# RasbperryPi register map
File version: 1
Registers are 32-bit, read-write, reset 0x0 unless marked. A register's access mark holds for its fields unless they carry their own. Offsets are from the block's base; [hi:lo] are bit positions; {n}, {i} and the like mark numbered series; 'fields as' and 'values as' point back to an identical list.

## USB — Derived from usb.h apb_id: 0x75736230
Base 0x7E980000
0x00 GOTGCTL 20-bit reset not defined
  [19] B_SES_VLD, [18] A_SES_VLD, [17] DBNC_TIME, [16] CON_ID_STS, [15:12] _, [11] DEV_HNP_EN, [10] HST_SET_HNP_EN, [9] HNP_REQ, [8] HST_NEG_SCS, [7:2] _, [1] SES_REQ, [0] SES_REQ_SCS
0x00 HPTXFSIZ reset not defined
  [31:0] data
0x00 HCFG 3-bit reset not defined
  [2] LS_SUPP, [1:0] LS_PHY_CLK_SEL
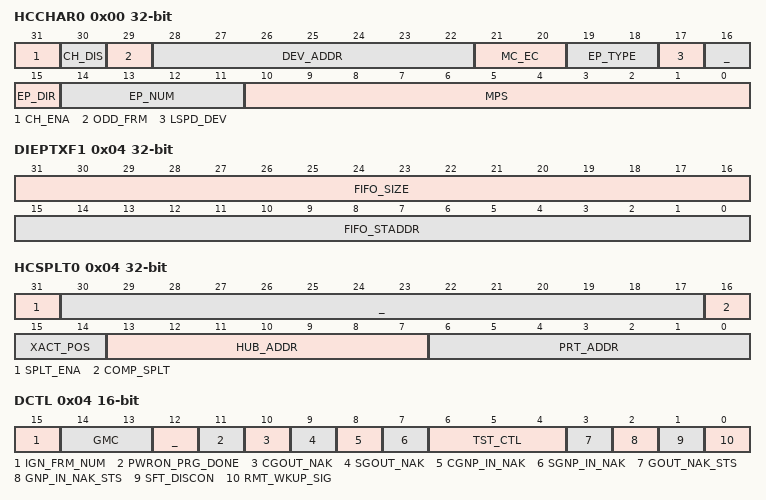
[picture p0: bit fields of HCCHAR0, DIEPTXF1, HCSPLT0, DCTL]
0x00 HCCHAR0 reset not defined
  [31] CH_ENA, [30] CH_DIS, [29] ODD_FRM, [28:22] DEV_ADDR, [21:20] MC_EC, [19:18] EP_TYPE, [17] LSPD_DEV, [16] _, [15] EP_DIR, [14:11] EP_NUM, [10:0] MPS
0x00 DCFG 26-bit reset not defined
  [25:24] PER_SCH_INTV, [23] DESC_DMA, [22:18] EP_MIS_CNT, [17:13] _, [12:11] PER_FR_INT, [10:4] DEV_ADDR, [3] _, [2] NZ_STS_OUT_HSHK, [1:0] DEV_SPD
0x00 DIEPCTL0 reset not defined
  [31] ENA, [30] DIS, [29] SET_D1_PID, [29] SET_ODD_FR, [28] SET_D0_PID, [28] SET_EVEN_FR, [27] SNAK, [26] CNAK, [25:22] TXF_NUM, [21] STALL, [20] SNP, [19:18] TYPE, [17] NAK_STS, [16] DPID, [16] EO_FR_NUM, [15] USB_ACT_EP, [14:11] NEXT_EP, [10:0] MPS
0x00 DIEPCTL8 reset not defined
  [31:0] data
0x00 DOEPCTL0 reset not defined
  fields as DIEPCTL0
0x00 DOEPCTL8 reset not defined
  [31:0] data
0x00 PCGCR 4-bit reset not defined
  [3] RST_PDWN_MODULE, [2] PWR_CLMP, [1] GATE_HCLK, [0] STOP_PCLK
0x00 DFIFO{i} reset not defined (i=0..15)
  [31:0] data
0x04 GOTGINT 20-bit reset not defined
  [19] DBNCE_DONE, [18] A_DEV_TOUT_CHG, [17] HST_NEG_DET, [16:10] _, [9] HST_NEG_SUC_STS_CHG, [8] SES_REQ_SUC_STS_CHG, [7:3] _, [2] SES_END_DET, [1:0] _
{0x0+4i} DPTXFSIZ{i} reset not defined (i=1..15)
  [31:0] data
0x04 DIEPTXF1 reset not defined
  [31:16] FIFO_SIZE, [15:0] FIFO_STADDR
0x04 HFIR 16-bit reset not defined
  [15:0] IN
0x04 HCSPLT0 reset not defined
  [31] SPLT_ENA, [30:17] _, [16] COMP_SPLT, [15:14] XACT_POS, [13:7] HUB_ADDR, [6:0] PRT_ADDR
0x04 DCTL 16-bit reset not defined
  [15] IGN_FRM_NUM, [14:13] GMC, [12] _, [11] PWRON_PRG_DONE, [10] CGOUT_NAK, [9] SGOUT_NAK, [8] CGNP_IN_NAK, [7] SGNP_IN_NAK, [6:4] TST_CTL, [3] GOUT_NAK_STS, [2] GNP_IN_NAK_STS, [1] SFT_DISCON, [0] RMT_WKUP_SIG
0x08 GAHBCFG 9-bit reset not defined
  [8] P_TXF_EMP_LVL, [7] NP_TXF_EMP_LVL, [6] _, [5] DMA_EN, [4:1] H_BST_LEN, [0] GLBL_INTR_MSK
{0x0+4i} DIEPTXF{i} reset not defined (i=2..15)
  [31:0] data
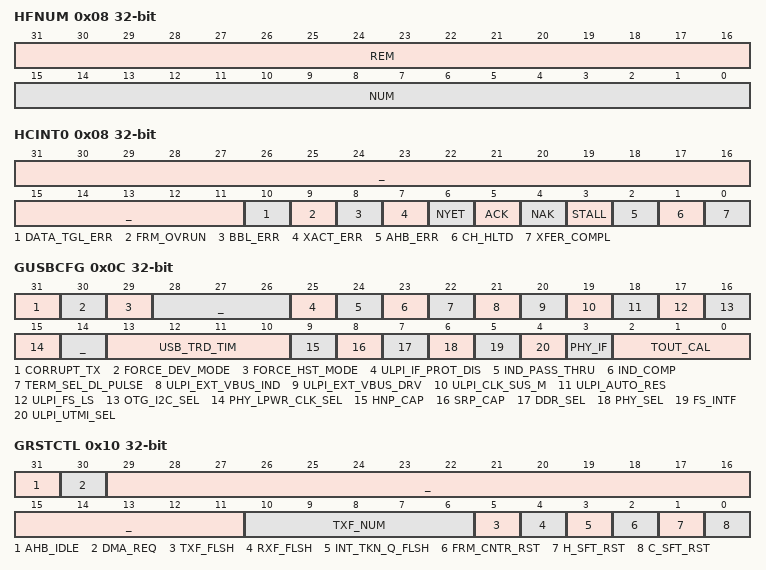
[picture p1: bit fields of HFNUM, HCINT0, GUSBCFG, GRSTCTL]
0x08 HFNUM reset not defined
  [31:16] REM, [15:0] NUM
0x08 HCINT0 reset not defined
  [31:11] _, [10] DATA_TGL_ERR, [9] FRM_OVRUN, [8] BBL_ERR, [7] XACT_ERR, [6] NYET, [5] ACK, [4] NAK, [3] STALL, [2] AHB_ERR, [1] CH_HLTD, [0] XFER_COMPL
0x08 DSTS 22-bit reset not defined
  [21:8] SOF_FN, [7:4] _, [3] ERRTIC_ERR, [2:1] ENUM_SPD, [0] SUSP_STS
0x08 DIEPINT0 reset not defined
  [31:10] _, [9] BNA, [8] TX_FIFO_UNDRN, [8] OUT_PKT_ERR, [7] TXF_EMPTY, [6] IN_EP_NAK_EFF, [6] BACK2BACK_SETUP, [5] IN_TKN_EP_MIS, [5] STS_PHSE_RCVD, [4] IN_TKN_TXFEMP, [4] OUT_TKN_EP_DIS, [3] TIMEOUT, [3] SETUP, [2] AHB_ERR, [1] EP_DISBLD, [0] XFER_COMPL
0x08 DIEPINT8 reset not defined
  [31:0] data
0x08 DOEPINT0 reset not defined
  fields as DIEPINT0
0x08 DOEPINT8 reset not defined
  [31:0] data
0x0C GUSBCFG reset not defined
  [31] CORRUPT_TX, [30] FORCE_DEV_MODE, [29] FORCE_HST_MODE, [28:26] _, [25] ULPI_IF_PROT_DIS, [24] IND_PASS_THRU, [23] IND_COMP, [22] TERM_SEL_DL_PULSE, [21] ULPI_EXT_VBUS_IND, [20] ULPI_EXT_VBUS_DRV, [19] ULPI_CLK_SUS_M, [18] ULPI_AUTO_RES, [17] ULPI_FS_LS, [16] OTG_I2C_SEL, [15] PHY_LPWR_CLK_SEL, [14] _, [13:10] USB_TRD_TIM, [9] HNP_CAP, [8] SRP_CAP, [7] DDR_SEL, [6] PHY_SEL, [5] FS_INTF, [4] ULPI_UTMI_SEL, [3] PHY_IF, [2:0] TOUT_CAL
{0xC+0x20*i} HCINTMSK{i} reset not defined (i=0..7)
  [31:0] data
0x10 GRSTCTL reset not defined
  [31] AHB_IDLE, [30] DMA_REQ, [29:11] _, [10:6] TXF_NUM, [5] TXF_FLSH, [4] RXF_FLSH, [3] INT_TKN_Q_FLSH, [2] FRM_CNTR_RST, [1] H_SFT_RST, [0] C_SFT_RST
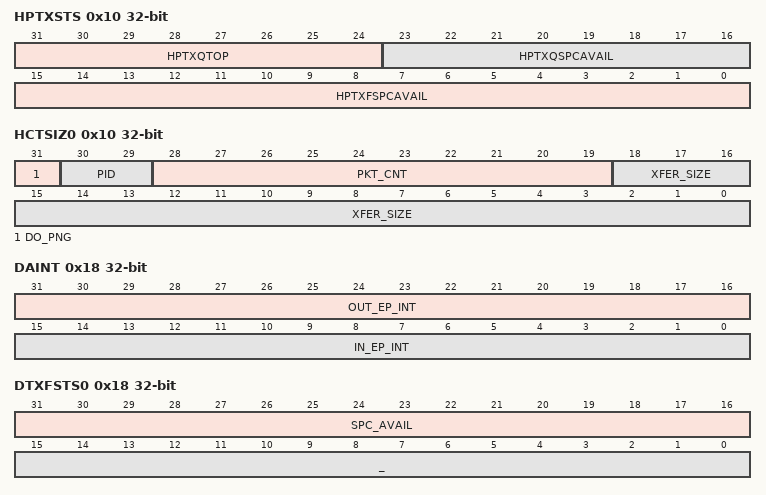
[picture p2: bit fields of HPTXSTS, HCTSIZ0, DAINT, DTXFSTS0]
0x10 HPTXSTS reset not defined
  [31:24] HPTXQTOP, [23:16] HPTXQSPCAVAIL, [15:0] HPTXFSPCAVAIL
0x10 HCTSIZ0 reset not defined
  [31] DO_PNG, [30:29] PID, [28:19] PKT_CNT, [18:0] XFER_SIZE
0x10 DIEPMSK reset not defined
  [31:0] data
0x10 DIEPTSIZ0 reset not defined
  [31] _, [30:29] SUP_CNT, [30:29] RX_DPID, [30:29] MC, [28:19] PKT_CNT, [18:0] XFERSIZE
0x10 DIEPTSIZ8 reset not defined
  [31:0] data
0x10 DOEPTSIZ0 reset not defined
  fields as DIEPTSIZ0
0x10 DOEPTSIZ8 reset not defined
  [31:0] data
0x14 GINTSTS reset not defined
  [31:0] data
0x14 HAINT reset not defined
  [31:0] data
{0x14+0x20*i} HCDMA{i} reset not defined (i=0..7)
  [31:0] data
0x14 DOEPMSK reset not defined
  [31:0] data
{0x14+0x20*i} DIEPDMA{i} reset not defined (i=0..7)
  [31:0] data
0x14 DIEPDMA8 reset not defined
  [31:0] data
{0x14+0x20*i} DOEPDMA{i} reset not defined (i=0..7)
  [31:0] data
0x14 DOEPDMA8 reset not defined
  [31:0] data
0x18 GINTMSK reset not defined
  [31] WK_UP_INT, [30] SESS_REQ_INT, [29] DISCONN_INT, [28] CON_ID_STS_CHNG, [27] _, [26] P_TXF_EMP, [25] HCH_INT, [24] PRT_INT, [23] _, [22] FET_SUSP, [21] INCOMPL_P, [21] INCOMPL_ISO_OUT, [20] INCOMPL_ISO_IN, [19] OEP_INT, [18] IEP_INT, [17] EP_MIS, [16] _, [15] EOPF, [14] ISO_OUT_DROP, [13] ENUM_DONE, [12] USB_RST, [11] USB_SUSP, [10] ERLY_SUSP, [9] I2C_INT, [8] ULPI_CK_INT, [7] GOUT_NAK_EFF, [6] GIN_N_NAK_EFF, [5] NP_TXF_EMP, [4] RXF_LVL, [3] SOF, [2] OTG_INT, [1] MODE_MIS, [0] CUR_MOD
0x18 HAINTMSK reset not defined
  [31:0] data
0x18 DAINT reset not defined
  [31:16] OUT_EP_INT, [15:0] IN_EP_INT
0x18 DTXFSTS0 reset not defined
  [31:16] SPC_AVAIL, [15:0] _
{0x18+0x20*i} DIEPDMAB{i} reset not defined (i=0..7)
  [31:0] data
0x18 DTXFSTS8 reset not defined
  [31:0] data
0x18 DIEPDMAB8 reset not defined
  [31:0] data
0x1C GRXSTSR reset not defined
  [31:0] data
0x1C DOEPDMAB{i} reset not defined (i=0..15)
  [31:0] data
0x20 GRXSTSP 25-bit reset not defined
  [24:21] DEV_FN, [20:17] HST_PKT_STS, [20:17] DEV_PKT_STS, [16:15] HST_DPID, [16:15] DEV_DPID, [14:4] HST_BCNT, [14:4] DEV_BCNT, [3:0] HST_CH_NUM, [3:0] DEV_EP_NUM
{0x0+0x20*i} HCCHAR{i} reset not defined (i=1..7)
  [31:0] data
0x20 DTKNQR1 reset not defined
  [31:0] data
{0x0+0x20*i} DIEPCTL{i} reset not defined (i=1..7)
  [31:0] data
0x20 DIEPCTL9 reset not defined
  [31:0] data
{0x0+0x20*i} DOEPCTL{i} reset not defined (i=1..7)
  [31:0] data
0x20 DOEPCTL9 reset not defined
  [31:0] data
0x24 GRXFSIZ 16-bit reset not defined
  [15:0] GRXF_DEP
{0x4+0x20*i} HCSPLT{i} reset not defined (i=1..7)
  [31:0] data
0x24 DTKNQR2 reset not defined
  [31:0] data
0x28 GNPTXFSIZ reset not defined
  [31:16] NP_TXF_DEP, [31:16] IN_EP_TXF0_DEP, [15:0] NP_TXF_ST_ADDR, [15:0] IN_EP_TXF0_ST_ADDR
{0x8+0x20*i} HCINT{i} reset not defined (i=1..7)
  [31:0] data
0x28 DVBUSDIS 16-bit reset not defined
  [15:0] data
{0x8+0x20*i} DIEPINT{i} reset not defined (i=1..7)
  [31:0] data
0x28 DIEPINT9 reset not defined
  [31:0] data
{0x8+0x20*i} DOEPINT{i} reset not defined (i=1..7)
  [31:0] data
0x28 DOEPINT9 reset not defined
  [31:0] data
0x2C GNPTXSTS 31-bit reset not defined
  [30:24] TX_Q_TOP, [23:16] TX_Q_SPC_AVAIL, [15:0] TXF_SPC_AVAIL
0x2C DVBUSPULSE 12-bit reset not defined
  [11:0] PULSE
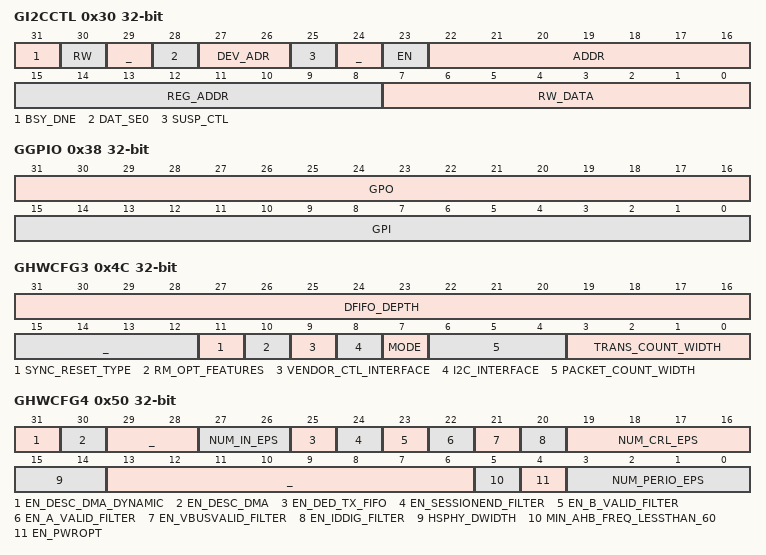
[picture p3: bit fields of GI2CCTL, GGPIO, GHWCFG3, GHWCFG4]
0x30 GI2CCTL reset not defined
  [31] BSY_DNE, [30] RW, [29] _, [28] DAT_SE0, [27:26] DEV_ADR, [25] SUSP_CTL, [24] _, [23] EN, [22:16] ADDR, [15:8] REG_ADDR, [7:0] RW_DATA
{0x10+0x20*i} HCTSIZ{i} reset not defined (i=1..7)
  [31:0] data
0x30 DTKNQR3 reset not defined
  [31:0] data
0x30 DTHRCTL 28-bit reset not defined
  [27] ARB_PRK_EN, [26:17] RX_THR_LEN, [16] RX_THR_EN, [15:11] _, [10:2] TX_THR_LEN, [1] ISO_THR_EN, [0] NON_ISO_THR_EN
{0x10+0x20*i} DIEPTSIZ{i} reset not defined (i=1..7)
  [31:0] data
0x30 DIEPTSIZ9 reset not defined
  [31:0] data
{0x10+0x20*i} DOEPTSIZ{i} reset not defined (i=1..7)
  [31:0] data
0x30 DOEPTSIZ9 reset not defined
  [31:0] data
0x34 GPVNDCTL reset not defined
  [31] DIS_ULPI_DRVR, [30:28] _, [27] STS_DONE, [26] STS_BSY, [25] NEW_REG_REQ, [24:23] _, [22] REG_WR, [21:16] REG_ADDR, [15:14] _, [11:8] CTRL_UTMI, [13:8] CTRL_ULPI, [7:0] REG_DATA
0x34 DTKNQR4 reset not defined
  [31:0] data
0x34 DIEPEMPMSK 16-bit reset not defined
  [15:0] EP_TXF_EMP_MSK
0x34 DIEPDMA9 reset not defined
  [31:0] data
0x34 DOEPDMA9 reset not defined
  [31:0] data
0x38 GGPIO reset not defined
  [31:16] GPO, [15:0] GPI
{0x18+0x20*i} DTXFSTS{i} reset not defined (i=1..7)
  [31:0] data
0x38 DTXFSTS9 reset not defined
  [31:0] data
0x38 DIEPDMAB9 reset not defined
  [31:0] data
0x3C GUID reset not defined
  [31:0] data
0x40 GSNPSID reset not defined
  [31:0] data
0x40 HPRT 19-bit reset not defined
  [18:17] SPD, [16:13] TST_CTL, [12] PWR, [11:10] LN_STS, [9] _, [8] RST, [7] SUSP, [6] RES, [5] OVR_CURR_CHNG, [4] OVR_CURR_ACT, [3] EN_CHNG, [2] ENA, [1] CONN_DET, [0] CONN_STS
0x40 DIEPCTL10 reset not defined
  [31:0] data
0x40 DOEPCTL10 reset not defined
  [31:0] data
0x44 GHWCFG1 reset not defined
  [31:0] data
0x48 GHWCFG2 31-bit reset not defined
  [30:26] TOKEN_QUEUE_DEPTH, [25:24] PERIO_TX_QUEUE_DEPTH, [23:22] NPERIO_TX_QUEUE_DEPTH, [21:20] _, [19] DFIFO_DYNAMIC, [18] EN_PERIO_HOST, [17] NUM_HOST_CHAN, [13] NUM_EPS, [17:10] _, [9:8] FSPHY_INTERFACE, [7:6] HSPHY_INTERFACE, [5] SINGLE_POINT, [4:3] ARCHITECTURE, [2:0] MODE
0x48 DIEPINT10 reset not defined
  [31:0] data
0x48 DOEPINT10 reset not defined
  [31:0] data
0x4C GHWCFG3 reset not defined
  [31:16] DFIFO_DEPTH, [15:12] _, [11] SYNC_RESET_TYPE, [10] RM_OPT_FEATURES, [9] VENDOR_CTL_INTERFACE, [8] I2C_INTERFACE, [7] MODE, [6:4] PACKET_COUNT_WIDTH, [3:0] TRANS_COUNT_WIDTH
0x50 GHWCFG4 reset not defined
  [31] EN_DESC_DMA_DYNAMIC, [30] EN_DESC_DMA, [29:28] _, [27:26] NUM_IN_EPS, [25] EN_DED_TX_FIFO, [24] EN_SESSIONEND_FILTER, [23] EN_B_VALID_FILTER, [22] EN_A_VALID_FILTER, [21] EN_VBUSVALID_FILTER, [20] EN_IDDIG_FILTER, [19:16] NUM_CRL_EPS, [15:14] HSPHY_DWIDTH, [13:6] _, [5] MIN_AHB_FREQ_LESSTHAN_60, [4] EN_PWROPT, [3:0] NUM_PERIO_EPS
0x50 DIEPTSIZ10 reset not defined
  [31:0] data
0x50 DOEPTSIZ10 reset not defined
  [31:0] data
0x54 GLPMCFG reset not defined
  [31:0] data
0x54 GAXIDEV reset not defined
  [31:0] data
0x54 DIEPDMA10 reset not defined
  [31:0] data
0x54 DOEPDMA10 reset not defined
  [31:0] data
0x58 DTXFSTS10 reset not defined
  [31:0] data
0x58 DIEPDMAB10 reset not defined
  [31:0] data
0x60 DIEPCTL11 reset not defined
  [31:0] data
0x60 DOEPCTL11 reset not defined
  [31:0] data
0x68 DIEPINT11 reset not defined
  [31:0] data
0x68 DOEPINT11 reset not defined
  [31:0] data
0x70 DIEPTSIZ11 reset not defined
  [31:0] data
0x70 DOEPTSIZ11 reset not defined
  [31:0] data
0x74 DIEPDMA11 reset not defined
  [31:0] data
0x74 DOEPDMA11 reset not defined
  [31:0] data
0x78 DTXFSTS11 reset not defined
  [31:0] data
0x78 DIEPDMAB11 reset not defined
  [31:0] data
0x80 GMDIOCSR 16-bit reset not defined
  [15:0] data
0x80 DIEPCTL12 reset not defined
  [31:0] data
0x80 DOEPCTL12 reset not defined
  [31:0] data
0x84 GMDIOGEN reset not defined
  [31:0] data
0x88 GVBUSDRV 16-bit reset not defined
  [15:0] data
0x88 DIEPINT12 reset not defined
  [31:0] data
0x88 DOEPINT12 reset not defined
  [31:0] data
0x90 DIEPTSIZ12 reset not defined
  [31:0] data
0x90 DOEPTSIZ12 reset not defined
  [31:0] data
0x94 DIEPDMA12 reset not defined
  [31:0] data
0x94 DOEPDMA12 reset not defined
  [31:0] data
0x98 DTXFSTS12 reset not defined
  [31:0] data
0x98 DIEPDMAB12 reset not defined
  [31:0] data
0xA0 DIEPCTL13 reset not defined
  [31:0] data
0xA0 DOEPCTL13 reset not defined
  [31:0] data
0xA8 DIEPINT13 reset not defined
  [31:0] data
0xA8 DOEPINT13 reset not defined
  [31:0] data
0xB0 DIEPTSIZ13 reset not defined
  [31:0] data
0xB0 DOEPTSIZ13 reset not defined
  [31:0] data
0xB4 DIEPDMA13 reset not defined
  [31:0] data
0xB4 DOEPDMA13 reset not defined
  [31:0] data
0xB8 DTXFSTS13 reset not defined
  [31:0] data
0xB8 DIEPDMAB13 reset not defined
  [31:0] data
0xC0 DIEPCTL14 reset not defined
  [31:0] data
0xC0 DOEPCTL14 reset not defined
  [31:0] data
0xC8 DIEPINT14 reset not defined
  [31:0] data
0xC8 DOEPINT14 reset not defined
  [31:0] data
0xD0 DIEPTSIZ14 reset not defined
  [31:0] data
0xD0 DOEPTSIZ14 reset not defined
  [31:0] data
0xD4 DIEPDMA14 reset not defined
  [31:0] data
0xD4 DOEPDMA14 reset not defined
  [31:0] data
0xD8 DTXFSTS14 reset not defined
  [31:0] data
0xD8 DIEPDMAB14 reset not defined
  [31:0] data
0xE0 DIEPCTL15 reset not defined
  [31:0] data
0xE0 DOEPCTL15 reset not defined
  [31:0] data
0xE8 DIEPINT15 reset not defined
  [31:0] data
0xE8 DOEPINT15 reset not defined
  [31:0] data
0xF0 DIEPTSIZ15 reset not defined
  [31:0] data
0xF0 DOEPTSIZ15 reset not defined
  [31:0] data
0xF4 DIEPDMA15 reset not defined
  [31:0] data
0xF4 DOEPDMA15 reset not defined
  [31:0] data
0xF8 DTXFSTS15 reset not defined
  [31:0] data
0xF8 DIEPDMAB15 reset not defined
  [31:0] data
